# Template register map
Vendor: VendorName Co.Ltd; Series: SeriesName; File version: 1.2
CPU: CM7 r0p1, little endian, MPU, FPU, 4 interrupt priority bits
Registers are 32-bit, read-write, no defined reset value unless marked. A register's access mark holds for its fields unless they carry their own. Offsets are from the block's base; [hi:lo] are bit positions; {n}, {i} and the like mark numbered series; 'fields as' and 'values as' point back to an identical list.

## PWR — Power Control
Base 0x40020000
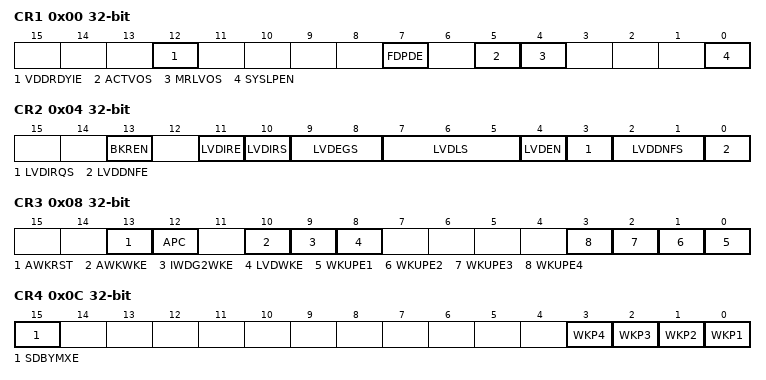
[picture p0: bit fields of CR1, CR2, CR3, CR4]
0x00 CR1 — PWR power control register 1
  [12] VDDRDYIE — PWR VDDRDYIE bit: VDD power stable interruption enable
  [7] FDPDE — PWR FDPDE bit: whether FLASH enter low-power consumption mode in stop mode
  [5] ACTVOS — PWR ACTVOS bit: LDO output voltage select in normal mode
  [4] MRLVOS — PWR MRLVOS bit: LDO output voltage select in stop mode
  [0] SYSLPEN — PWR SYSLPEN bit: whether permit enter system low-power consumption mode
0x04 CR2 — PWR power control register 2
  [13] BKREN — PWR BKREN bit: backup LDO enable
  [11] LVDIRE — PWR LVDIRE bit: LVD interrupt and reset enable
  [10] LVDIRS — PWR LVDIRS bit: LVD interrupt and reset select
  [9:8] LVDEGS — PWR LVDEGS[1:0] bit: LVD detection edge select
  [7:5] LVDLS — PWR LVDLS[2:0] bit: LVD detection voltage value select
  [4] LVDEN — PWR LVDEN bit: LVD detection voltage enable
  [3] LVDIRQS — PWR LVDIRQS bit: LVD shiled interruption select
  [2:1] LVDDNFS — PWR LVDDNFS[1:0] bit: LVD digital filter samping clock select
  [0] LVDDNFE — PWR LVDDNFE bit: LVD digital filter enable
0x08 CR3 — PWR power control register 3
  [13] AWKRST — PWR AWKRST bit: AWK software reset control
  [12] APC — PWR APC bit: global enable for upward or downward pull in the high-pressure domain
  [10] AWKWKE — PWR AWKWKE bit: AWK wakeup enable control
  [9] IWDG2WKE — PWR IWDG2WKE bit: IWDG2 wakeup enable control
  [8] LVDWKE — PWR LVDWKE bit: LVD wakeup enable control
  [n-1] WKUPE{n} (n=1..4) — PWR WKUPE{n} bit: enable wakeup pin WKUP{n}
0x0C CR4 — PWR power control register 4
  [15] SDBYMXE — PWR SDBYMXE bit: standby wakeup reset pull-down enable
  [n-1] WKP{n} (n=1..4) — PWR WKP{n} bit: wakeup pin WKUP{n} polarity
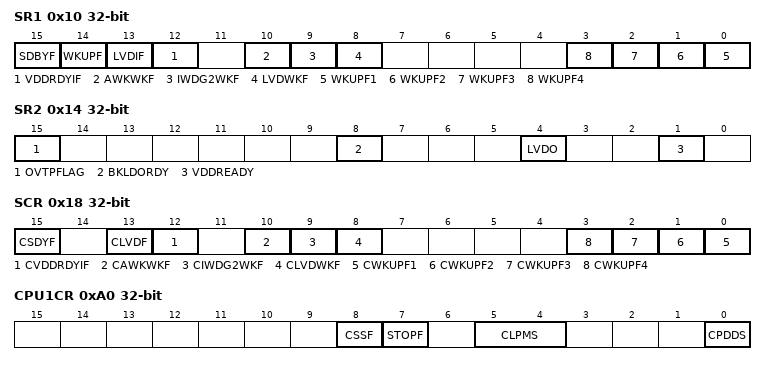
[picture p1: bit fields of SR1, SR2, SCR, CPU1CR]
0x10 SR1 ro — PWR power status register 1
  [15] SDBYF — PWR SDBYF bit: standby flag
  [14] WKUPF — PWR WKUPF bit: combination of all wakeup flag
  [13] LVDIF — PWR LVDIF bit: LVD detection voltage flag in interruption mode
  [12] VDDRDYIF — PWR VDDRDYIF bit: VDD interrupt flag
  [10] AWKWKF — PWR AWKWKF bit: AWK standby wakeup flag
  [9] IWDG2WKF — PWR IWDG2WKF bit: IWDG2 standby wakeup flag
  [8] LVDWKF — PWR LVDWKF bit: LVD standby wakeup flag
  [n-1] WKUPF{n} (n=1..4) — PWR WKUPF{n} bit: wakeup flag of WKUPF{n}
0x14 SR2 ro — PWR power status register 2
  [15] OVTPFLAG — PWR OVTPFLAG bit: over temperature protect flag
  [8] BKLDORDY — PWR BKLDORDY bit: backup LDO stable flag
  [4] LVDO — PWR LVDO bit: LVD output value
  [1] VDDREADY — PWR VDDREADY bit: VDD voltage stable flag
0x18 SCR wo — PWR power status clear register
  [15] CSDYF — PWR CSDYF bit: standby flag clear 0 control bit
  [13] CLVDF — PWR CLVDF bit: LVD detection flag clear bit
  [12] CVDDRDYIF — PWR CVDDRDYIF bit: VDDRDYIF clear bit
  [10] CAWKWKF — PWR CAWKWKF bit: AWK wakeup flag clear bit
  [9] CIWDG2WKF — PWR CIWDG2WKF bit: IWDG2 wakeup flag clear bit
  [8] CLVDWKF — PWR CLVDWKF bit: LVD wakeup flag clear bit
  [n-1] CWKUPF{n} (n=1..4) — PWR CWKUPF{n} bit: wakeup flag clear of WKUPF{n}
0x20 PAPECR1 — PWR PORTA PULL enable control register 1
  [15:0] PE — PWR PE[15:0] bit: pin0~15 enable for upward or downward pull on open domain
0x24 PAPECR2 — PWR PORTA PULL enable control register 2
  [15:0] PE — PWR PE[15:0] bit: pin16~31 enable for upward or downward pull on open domain
0x28 PAPSCR1 — PWR PORTA PULL select control register 1
  [15:0] PS — PWR PS[15:0] bit: pin0~15 select for upward or downward pull on open domain
0x2C PAPSCR2 — PWR PORTA PULL select control register 2
  [15:0] PS — PWR PS[15:0] bit: pin16~31 select for upward or downward pull on open domain
0x30 PBPECR1 — PWR PORTB PULL enable control register 1
  fields as PAPECR1
0x34 PBPECR2 — PWR PORTB PULL enable control register 2
  fields as PAPECR2
0x38 PBPSCR1 — PWR PORTB PULL select control register 1
  fields as PAPSCR1
0x3C PBPSCR2 — PWR PORTB PULL select control register 2
  fields as PAPSCR2
0x40 PCPECR1 — PWR PORTC PULL enable control register 1
  fields as PAPECR1
0x44 PCPECR2 — PWR PORTC PULL enable control register 2
  fields as PAPECR2
0x48 PCPSCR1 — PWR PORTC PULL select control register 1
  fields as PAPSCR1
0x4C PCPSCR2 — PWR PORTC PULL select control register 2
  fields as PAPSCR2
0x50 PDPECR1 — PWR PORTD PULL enable control register 1
  [10:3] PE — PWR PE[7:0] bit: pin3~10 enable for upward or downward pull on open domain
0x58 PDPSCR1 — PWR PORTD PULL select control register 1
  [10:3] PS — PWR PS[7:0] bit: pin3~10 select for upward or downward pull on open domain
0x60 PEPECR1 — PWR PORTE PULL enable control register 1
  [5] PE — PWR PE bit: pin5 enable for upward or downward pull on open domain
0x68 PEPSCR1 — PWR PORTE PULL select control register 1
  [5] PS — PWR PS bit: pin5 select for upward or downward pull on open domain
0x70 PFPECR1 — PWR PORTF PULL enable control register 1
  [15:12] PE — PWR PE[3:0] bit: pin12~15 enable for upward or downward pull on open domain
0x74 PFPECR2 — PWR PORTF PULL enable control register 2
  [8:0] PE — PWR PE[8:0] bit: pin16~24 enable for upward or downward pull on open domain
0x78 PFPSCR1 — PWR PORTF PULL select control register 1
  [15:12] PS — PWR PS[3:0] bit: pin12~15 select for upward or downward pull on open domain
0x7C PFPSCR2 — PWR PORTF PULL select control register 2
  [8:0] PS — PWR PS[8:0] bit: pin16~24 select for upward or downward pull on open domain
0x80 PGPECR1 — PWR PORTG PULL enable control register 1
  fields as PAPECR1
0x84 PGPECR2 — PWR PORTG PULL enable control register 2
  fields as PAPECR2
0x88 PGPSCR1 — PWR PORTG PULL select control register 1
  fields as PAPSCR1
0x8C PGPSCR2 — PWR PORTG PULL select control register 2
  fields as PAPSCR2
0x90 PHPECR1 — PWR PORTH PULL enable control register 1
  fields as PAPECR1
0x94 PHPECR2 — PWR PORTH PULL enable control register 2
  [0] PE — PWR PE bit: pin16 enable for upward or downward pull on open domain
0x98 PHPSCR1 — PWR PORTH PULL select control register 1
  [0] PS — PWR PS bit: pin0 select for upward or downward pull on open domain
0xA0 CPU1CR — PWR CPU1 control register
  [8] CSSF wo — PWR CSSF bit: clear stop flags
  [7] STOPF ro — PWR STOPF bit: STOP flag of CPU1
  [5:4] CLPMS ro — PWR CLPMS[1:0] bit: CPU1 low-power consumption status
  [0] CPDDS — PWR CPDDS bit: CPU1 power down select request in deep sleep mode
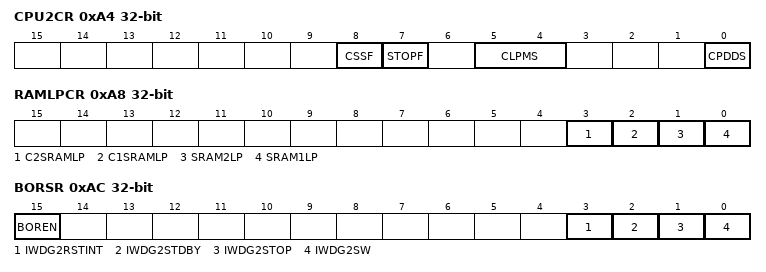
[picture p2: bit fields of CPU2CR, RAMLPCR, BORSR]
0xA4 CPU2CR — PWR CPU2 control register
  [8] CSSF wo — PWR CSSF bit: clear stop flags
  [7] STOPF ro — PWR STOPF bit: STOP flag of CPU2
  [5:4] CLPMS ro — PWR CLPMS[1:0] bit: CPU2 low-power consumption status
  [0] CPDDS — PWR CPDDS bit: CPU2 power down select request in deep sleep mode
0xA8 RAMLPCR — PWR RAM low-power consumption control register
  [3] C2SRAMLP — PWR C2SRAMLP bit: CPU2 SRAM low-power consumption control
  [2] C1SRAMLP — PWR C1SRAMLP bit: CPU1 SRAM low-power consumption control
  [1] SRAM2LP — PWR SRAM2LP bit: SRAM2 low-power consumption control
  [0] SRAM1LP — PWR SRAM1LP bit: SRAM1 low-power consumption control
0xAC BORSR ro — PWR BR power control register
  [15] BOREN — PWR BOREN bit: BOR detection voltage enable control
  [3] IWDG2RSTINT — PWR IWDG2RSTINT bit: IWDG2 overflow reset and interrupt mode select
  [2] IWDG2STDBY — PWR IWDG2STDBY bit: IWDG2 standby mode stop control
  [1] IWDG2STOP — PWR IWDG2STOP bit: IWDG2 stop mode stop control
  [0] IWDG2SW — PWR IWDG2SW bit: IWDG2 start way select
